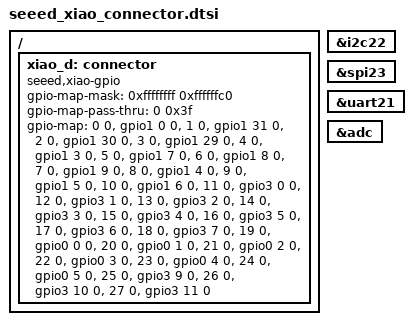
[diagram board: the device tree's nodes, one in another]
/*
 * Copyright (c) 2025 Seeed Technology Co., Ltd.
 * SPDX-License-Identifier: Apache-2.0
 */

/ {
	xiao_d: connector {
		compatible = "seeed,xiao-gpio";
		#gpio-cells = <2>;
		gpio-map-mask = <0xffffffff 0xffffffc0>;
		gpio-map-pass-thru = <0 0x3f>;
		gpio-map = <0 0 &gpio1 0 0>,	/* D0 */
			   <1 0 &gpio1 31 0>,	/* D1 */
			   <2 0 &gpio1 30 0>,	/* D2 */
			   <3 0 &gpio1 29 0>,	/* D3 */
			   <4 0 &gpio1 3 0>,	/* D4 */
			   <5 0 &gpio1 7 0>,	/* D5 */
			   <6 0 &gpio1 8 0>,	/* D6 */
			   <7 0 &gpio1 9 0>,	/* D7 */
			   <8 0 &gpio1 4 0>,	/* D8 */
			   <9 0 &gpio1 5 0>,	/* D9 */
			   <10 0 &gpio1 6 0>,	/* D10 */
			   <11 0 &gpio3 0 0>,	/* D11 */
			   <12 0 &gpio3 1 0>,	/* D12 */
			   <13 0 &gpio3 2 0>,	/* D13 */
			   <14 0 &gpio3 3 0>,	/* D14 */
			   <15 0 &gpio3 4 0>,	/* D15 */
			   <16 0 &gpio3 5 0>,	/* D16 */
			   <17 0 &gpio3 6 0>,	/* D17 */
			   <18 0 &gpio3 7 0>,	/* D18 */
			   <19 0 &gpio0 0 0>,	/* D19 */
			   <20 0 &gpio0 1 0>,	/* D20 */
			   <21 0 &gpio0 2 0>,	/* D21 */
			   <22 0 &gpio0 3 0>,	/* D22 */
			   <23 0 &gpio0 4 0>,	/* D23 */
			   <24 0 &gpio0 5 0>,	/* D24 */
			   <25 0 &gpio3 9 0>,	/* D25 */
			   <26 0 &gpio3 10 0>,	/* D26 */
			   <27 0 &gpio3 11 0>;	/* D27 */
	};
};

xiao_i2c: &i2c22 {};

xiao_spi: &spi23 {};

xiao_serial: &uart21 {};

xiao_adc: &adc {};
